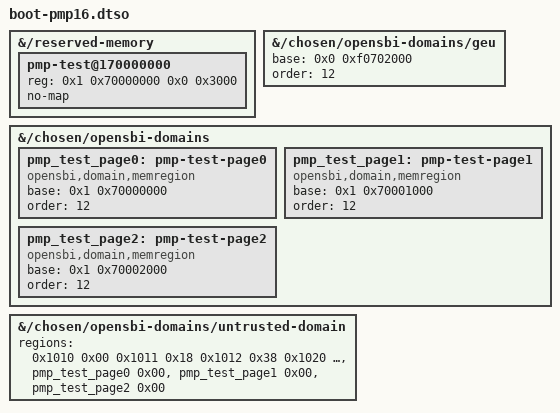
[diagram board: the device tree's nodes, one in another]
/dts-v1/;
/plugin/;

/* Capacity test for boot.dts. Keep the three pages out of the Linux allocator. */
&{/reserved-memory} {
	#address-cells = <2>;
	#size-cells = <2>;
	pmp-test@170000000 {
		reg = <0x1 0x70000000 0x0 0x3000>;
		no-map;
	};
};

&{/chosen/opensbi-domains/geu} {
	base = <0x0 0xf0702000>;
	order = <12>;
};

&{/chosen/opensbi-domains} {
	pmp_test_page0: pmp-test-page0 {
		compatible = "opensbi,domain,memregion";
		base = <0x1 0x70000000>;
		order = <12>;
	};
	pmp_test_page1: pmp-test-page1 {
		compatible = "opensbi,domain,memregion";
		base = <0x1 0x70001000>;
		order = <12>;
	};
	pmp_test_page2: pmp-test-page2 {
		compatible = "opensbi,domain,memregion";
		base = <0x1 0x70002000>;
		order = <12>;
	};
};

&{/chosen/opensbi-domains/untrusted-domain} {
	/* Keep the original Core, SHM, boot FDT and MMIO policy from boot.dts. */
	regions = <0x1010 0x00 0x1011 0x18 0x1012 0x38 0x1020 0x18
		   0x1030 0x00 0x1031 0x00 0x1032 0x00
		   &pmp_test_page0 0x00 &pmp_test_page1 0x00 &pmp_test_page2 0x00>;
};
